AUTOSAR XML (schema 4-0-3)
standard types defined: Boolean, UInt16, UInt32
package /AUTOSAR_Platform/DataConstrs
  range DC_Boolean: raw 0..1
  range DC_UInt16: raw 0..65535
package /PATAC/MSM/ComponentTypes
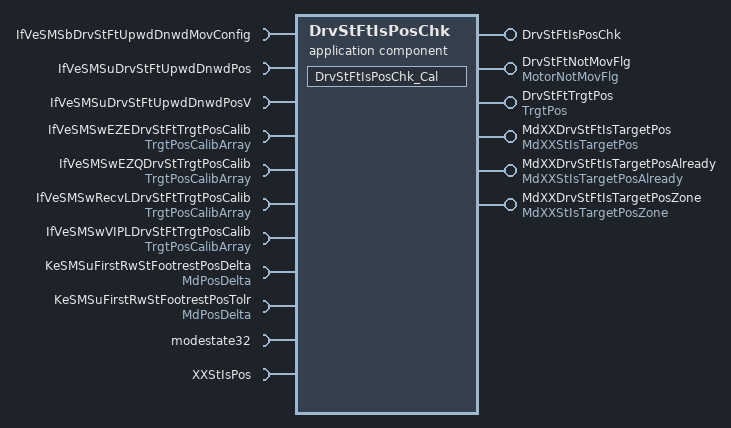
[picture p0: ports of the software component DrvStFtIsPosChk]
  application sw component type DrvStFtIsPosChk
    6 x provide port:
      DrvStFtIsPosChk: server-com-spec{operation=Cal, queue-length=1}, provided-interface=DrvStFtIsPosChk
      DrvStFtNotMovFlg: nonqueued-sender-com-spec{data-element=MotorNotMovFlg/Val, init-value=0}, provided-interface=MotorNotMovFlg
      DrvStFtTrgtPos: nonqueued-sender-com-spec{data-element=TrgtPos/Val, init-value=4095}, provided-interface=TrgtPos
      MdXXDrvStFtIsTargetPos: nonqueued-sender-com-spec=data-element=MdXXStIsTargetPos/Val, provided-interface=MdXXStIsTargetPos
      MdXXDrvStFtIsTargetPosAlready: nonqueued-sender-com-spec=data-element=MdXXStIsTargetPosAlready/Val, provided-interface=MdXXStIsTargetPosAlready
      MdXXDrvStFtIsTargetPosZone: nonqueued-sender-com-spec=data-element=MdXXStIsTargetPosZone/Val, provided-interface=MdXXStIsTargetPosZone
    11 x require port:
      IfVeSMSbDrvStFtUpwdDnwdMovConfig: nonqueued-receiver-com-spec{data-element=IfVeSMSbDrvStFtUpwdDnwdMovConfig/Val, filter=data-filter-type=ALWAYS, init-value=0}, required-interface=IfVeSMSbDrvStFtUpwdDnwdMovConfig
      IfVeSMSuDrvStFtUpwdDnwdPos: nonqueued-receiver-com-spec{data-element=IfVeSMSuDrvStFtUpwdDnwdPos/Val, filter=data-filter-type=ALWAYS, init-value=0}, required-interface=IfVeSMSuDrvStFtUpwdDnwdPos
      IfVeSMSuDrvStFtUpwdDnwdPosV: nonqueued-receiver-com-spec{data-element=IfVeSMSuDrvStFtUpwdDnwdPosV/Val, filter=data-filter-type=ALWAYS, init-value=0}, required-interface=IfVeSMSuDrvStFtUpwdDnwdPosV
      IfVeSMSwEZEDrvStFtTrgtPosCalib: nonqueued-receiver-com-spec{data-element=TrgtPosArray, filter=data-filter-type=ALWAYS, init-value=[0, 0, 0]}, required-interface=TrgtPosCalibArray
      IfVeSMSwEZQDrvStTrgtPosCalib: nonqueued-receiver-com-spec{data-element=TrgtPosArray, filter=data-filter-type=ALWAYS, init-value=[0, 0, 0]}, required-interface=TrgtPosCalibArray
      IfVeSMSwRecvLDrvStFtTrgtPosCalib: nonqueued-receiver-com-spec{data-element=TrgtPosArray, filter=data-filter-type=ALWAYS, init-value=[0, 0, 0]}, required-interface=TrgtPosCalibArray
      IfVeSMSwVIPLDrvStFtTrgtPosCalib: nonqueued-receiver-com-spec{data-element=TrgtPosArray, filter=data-filter-type=ALWAYS, init-value=[0, 0, 0]}, required-interface=TrgtPosCalibArray
      KeSMSuFirstRwStFootrestPosDelta: parameter-require-com-spec{init-value=150, parameter=Val}, required-interface=MdPosDelta
      KeSMSuFirstRwStFootrestPosTolr: parameter-require-com-spec{init-value=150, parameter=Val}, required-interface=MdPosDelta
      modestate32: nonqueued-receiver-com-spec{data-element=modestate32/Val, filter=data-filter-type=ALWAYS, init-value=0}, required-interface=modestate32
      XXStIsPos: client-com-spec=Get, required-interface=XXStIsPos
    behavior DrvStFtIsPosChk_InternalBehavior
      operation invoked event OIT_DrvStFtIsPosChk_Cal_DrvStFtIsPosChk_Cal: start-on-event=DrvStFtIsPosChk_Cal, operation=DrvStFtIsPosChk.Cal
      runnable DrvStFtIsPosChk_Cal
        data-receive-point-by-arguments:
          8 x access:
            REC_IfVeSMSbDrvStFtUpwdDnwdMovConfig_Val: accessed-variable=IfVeSMSbDrvStFtUpwdDnwdMovConfig.Val
            REC_IfVeSMSuDrvStFtUpwdDnwdPos_Val: accessed-variable=IfVeSMSuDrvStFtUpwdDnwdPos.Val
            REC_IfVeSMSuDrvStFtUpwdDnwdPosV_Val: accessed-variable=IfVeSMSuDrvStFtUpwdDnwdPosV.Val
            REC_IfVeSMSwEZEDrvStFtTrgtPosCalib_TrgtPosArray: accessed-variable=IfVeSMSwEZEDrvStFtTrgtPosCalib.TrgtPosArray
            REC_IfVeSMSwEZQDrvStTrgtPosCalib_TrgtPosArray: accessed-variable=IfVeSMSwEZQDrvStTrgtPosCalib.TrgtPosArray
            REC_IfVeSMSwRecvLDrvStFtTrgtPosCalib_TrgtPosArray: accessed-variable=IfVeSMSwRecvLDrvStFtTrgtPosCalib.TrgtPosArray
            REC_IfVeSMSwVIPLDrvStFtTrgtPosCalib_TrgtPosArray: accessed-variable=IfVeSMSwVIPLDrvStFtTrgtPosCalib.TrgtPosArray
            REC_modestate32_Val: accessed-variable=modestate32.Val
        data-send-points:
          5 x access:
            SEND_DrvStFtNotMovFlg_Val: accessed-variable=DrvStFtNotMovFlg.Val
            SEND_DrvStFtTrgtPos_Val: accessed-variable=DrvStFtTrgtPos.Val
            SEND_MdXXDrvStFtIsTargetPos_Val: accessed-variable=MdXXDrvStFtIsTargetPos.Val
            SEND_MdXXDrvStFtIsTargetPosAlready_Val: accessed-variable=MdXXDrvStFtIsTargetPosAlready.Val
            SEND_MdXXDrvStFtIsTargetPosZone_Val: accessed-variable=MdXXDrvStFtIsTargetPosZone.Val
        parameter access PA_KeSMSuFirstRwStFootrestPosDelta_Val: accessed-parameter=KeSMSuFirstRwStFootrestPosDelta.Val
        parameter access PA_KeSMSuFirstRwStFootrestPosTolr_Val: accessed-parameter=KeSMSuFirstRwStFootrestPosTolr.Val
        sync call SC_XXStIsPos_Get: operation=XXStIsPos.Get, timeout=0
  swc implementation DrvStFtIsPosChk_Implementation: behavior=DrvStFtIsPosChk_InternalBehavior
    code-descriptors:
      code Default: artifact-descriptors=autosar-engineering-object={short-label=Default, category=SWSRC}
package /PATAC/MSM/ModeAdjust/CalPortInterface
  parameter interface MdPosDelta
    parameter data prototype Val: sw-calibration-access=READ-WRITE, type=UInt16
package /PATAC/MSM/ModeAdjust/DataType
  impl type TrgtPosCalibArray: category=ARRAY, sw-calibration-access=READ-ONLY, type-emitter=RTE  # 0:pos 1:max 2:min
    element Element: array-size=3, array-size-semantics=FIXED-SIZE, implementation-data-type=UInt16, invalid-value=0
package /PATAC/MSM/ModeAdjust/Interfaces
  sender receiver interface IfVeSMSuDrvStFtUpwdDnwdPosV: invalidation-policy{data-element=IfVeSMSuDrvStFtUpwdDnwdPosV/Val, handle-invalid=DONT-INVALIDATE}
    data Val: type=Implementation/Boolean
package /PATAC/MSM/ModeAdjust/PortInterface
  client server interface DrvStFtIsPosChk
    operation Cal
  client server interface XXStIsPos
    operation Get
      8 x arg, all with server-argument-impl-policy=USE-ARGUMENT-TYPE:
        PosV: type=DataTypes/Boolean, direction=IN
        Pos: type=UInt16, direction=IN
        CalibArray: type=TrgtPosCalibArray, direction=IN
        Delta: type=UInt16, direction=IN
        Tolr: type=UInt16, direction=IN
        IsPos: type=DataTypes/Boolean, direction=OUT
        IsPosZone: type=DataTypes/Boolean, direction=OUT
        IsPosAlready: type=DataTypes/Boolean, direction=OUT
  6 x sender receiver interface:
    MdXXStIsTargetPos: invalidation-policy{data-element=MdXXStIsTargetPos/Val, handle-invalid=DONT-INVALIDATE}
      data Val: type=UInt32
    MdXXStIsTargetPosAlready: invalidation-policy{data-element=MdXXStIsTargetPosAlready/Val, handle-invalid=DONT-INVALIDATE}
      data Val: type=UInt32
    MdXXStIsTargetPosZone: invalidation-policy{data-element=MdXXStIsTargetPosZone/Val, handle-invalid=DONT-INVALIDATE}
      data Val: type=UInt32
    modestate32: invalidation-policy{data-element=modestate32/Val, handle-invalid=DONT-INVALIDATE}
      data Val: type=UInt32
    MotorNotMovFlg: invalidation-policy{data-element=MotorNotMovFlg/Val, handle-invalid=DONT-INVALIDATE}
      data Val: type=Implementation/Boolean
    TrgtPosCalibArray: invalidation-policy{data-element=TrgtPosArray, handle-invalid=DONT-INVALIDATE}
      data TrgtPosArray: type=TrgtPosCalibArray  # 0:Pos 1:Max 2:Min
package /PATAC/MSM/PortInterfaces
  sender receiver interface IfVeSMSbDrvStFtUpwdDnwdMovConfig: invalidation-policy{data-element=IfVeSMSbDrvStFtUpwdDnwdMovConfig/Val, handle-invalid=DONT-INVALIDATE}
    data Val: type=Implementation/Boolean
  sender receiver interface IfVeSMSuDrvStFtUpwdDnwdPos: invalidation-policy{data-element=IfVeSMSuDrvStFtUpwdDnwdPos/Val, handle-invalid=DONT-INVALIDATE}
    data Val: type=UInt16
  sender receiver interface TrgtPos: invalidation-policy{data-element=TrgtPos/Val, handle-invalid=DONT-INVALIDATE}
    data Val: type=UInt16
